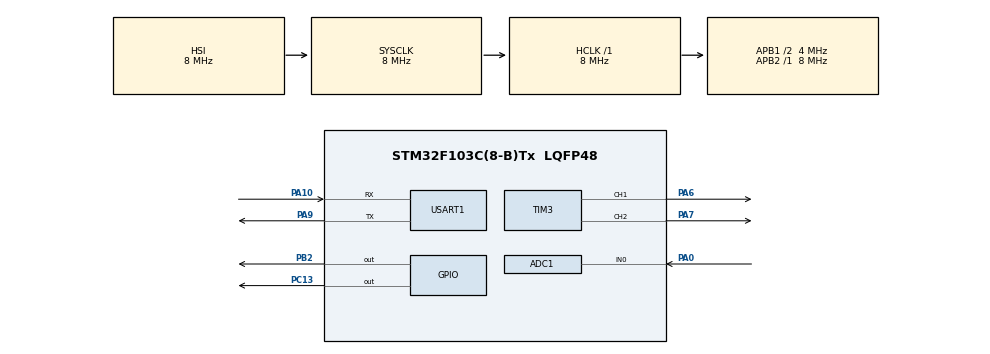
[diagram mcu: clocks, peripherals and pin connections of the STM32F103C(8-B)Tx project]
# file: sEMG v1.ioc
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ADC1.Channel-5\#ChannelRegularConversion=ADC_CHANNEL_0
ADC1.NbrOfConversionFlag=1
ADC1.Rank-5\#ChannelRegularConversion=1
ADC1.SamplingTime-5\#ChannelRegularConversion=ADC_SAMPLETIME_1CYCLE_5
ADC1.master=1
Mcu.Family=STM32F1
Mcu.Name=STM32F103C(8-B)Tx
Mcu.Package=LQFP48
NVIC.PriorityGroup=NVIC_PRIORITYGROUP_4
PA0-WKUP.Signal=ADCx_IN0
PA10.Mode=Asynchronous
PA10.Signal=USART1_RX
PA13.Signal=SYS_JTMS-SWDIO
PA14.Signal=SYS_JTCK-SWCLK
PA6.Signal=S_TIM3_CH1
PA7.Signal=S_TIM3_CH2
PA9.Mode=Asynchronous
PA9.Signal=USART1_TX
PB2.Signal=GPIO_Output
PC13-TAMPER-RTC.Signal=GPIO_Output
PD0-OSC_IN.Mode=HSE-External-Oscillator
PD0-OSC_IN.Signal=RCC_OSC_IN
PD1-OSC_OUT.Mode=HSE-External-Oscillator
PD1-OSC_OUT.Signal=RCC_OSC_OUT
ProjectManager.HeapSize=0x200
ProjectManager.StackSize=0x400
ProjectManager.TargetToolchain=STM32CubeIDE
RCC.ADCPresc=RCC_ADCPCLK2_DIV6
RCC.AHBFreq_Value=8000000
RCC.APB1CLKDivider=RCC_HCLK_DIV2
RCC.APB1Freq_Value=4000000
RCC.APB1TimFreq_Value=8000000
RCC.APB2Freq_Value=8000000
RCC.APB2TimFreq_Value=8000000
RCC.HCLKFreq_Value=8000000
RCC.PLLMUL=RCC_PLL_MUL9
RCC.PLLSourceVirtual=RCC_PLLSOURCE_HSE
RCC.SYSCLKFreq_VALUE=8000000
RCC.USBFreq_Value=72000000
SH.ADCx_IN0.0=ADC1_IN0,IN0
SH.S_TIM3_CH1.0=TIM3_CH1,PWM Generation1 CH1
SH.S_TIM3_CH2.0=TIM3_CH2,PWM Generation2 CH2
TIM3.Channel-PWM\ Generation1\ CH1=TIM_CHANNEL_1
TIM3.Channel-PWM\ Generation2\ CH2=TIM_CHANNEL_2
USART1.VirtualMode=VM_ASYNC
VP_SYS_VS_ND.Mode=No_Debug
board=custom

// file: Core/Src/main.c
/* USER CODE BEGIN Header */
/**
  ******************************************************************************
  * @file           : main.c
  * @brief          : Main program body
  ******************************************************************************
  * @attention
  *
  * Copyright (c) 2026 STMicroelectronics.
  * All rights reserved.
  *
  * This software is licensed under terms that can be found in the LICENSE file
  * in the root directory of this software component.
  * If no LICENSE file comes with this software, it is provided AS-IS.
  *
  ******************************************************************************
  */
/* USER CODE END Header */
#include "main.h"

ADC_HandleTypeDef hadc1;

TIM_HandleTypeDef htim3;

UART_HandleTypeDef huart1;

void SystemClock_Config(void);
static void MX_GPIO_Init(void);
static void MX_ADC1_Init(void);
static void MX_USART1_UART_Init(void);
static void MX_TIM3_Init(void);

int main(void)
{

  /* USER CODE BEGIN 1 */
		  __HAL_RCC_GPIOB_CLK_ENABLE();
		  GPIO_InitTypeDef testLed = {0};
		  testLed.Pin = GPIO_PIN_2;
		  testLed.Mode = GPIO_MODE_OUTPUT_PP;
		  testLed.Pull = GPIO_NOPULL;
		  testLed.Speed = GPIO_SPEED_FREQ_LOW;
		  HAL_GPIO_Init(GPIOB, &testLed);

		  for(int i = 0; i < 10; i++)
		  {
		    HAL_GPIO_TogglePin(GPIOB, GPIO_PIN_2);
		    for(volatile int j = 0; j < 500000; j++); // busy-wait delay, doesn't depend on clock config
		  }
  /* USER CODE END 1 */

  /* MCU Configuration--------------------------------------------------------*/

  /* Reset of all peripherals, Initializes the Flash interface and the Systick. */
  HAL_Init();

  /* Configure the system clock */
  SystemClock_Config();

  /* Initialize all configured peripherals */
  MX_GPIO_Init();
  MX_ADC1_Init();
  MX_USART1_UART_Init();
  MX_TIM3_Init();

  /* Infinite loop */
  while (1)
  {

    /* USER CODE BEGIN 3 */
    HAL_GPIO_TogglePin(GPIOB, GPIO_PIN_2);
    for(volatile int j = 0; j < 1000000; j++);
  }
  /* USER CODE END 3 */
}

void SystemClock_Config(void)
{
  RCC_OscInitTypeDef RCC_OscInitStruct = {0};
  RCC_ClkInitTypeDef RCC_ClkInitStruct = {0};
  RCC_PeriphCLKInitTypeDef PeriphClkInit = {0};

  /** Initializes the RCC Oscillators according to the specified parameters
  * in the RCC_OscInitTypeDef structure.
  */
  RCC_OscInitStruct.OscillatorType = RCC_OSCILLATORTYPE_HSI;
  RCC_OscInitStruct.HSIState = RCC_HSI_ON;
  RCC_OscInitStruct.HSICalibrationValue = RCC_HSICALIBRATION_DEFAULT;
  RCC_OscInitStruct.PLL.PLLState = RCC_PLL_NONE;
  if (HAL_RCC_OscConfig(&RCC_OscInitStruct) != HAL_OK)
  {
    Error_Handler();
  }

  /** Initializes the CPU, AHB and APB buses clocks
  */
  RCC_ClkInitStruct.ClockType = RCC_CLOCKTYPE_HCLK|RCC_CLOCKTYPE_SYSCLK
                              |RCC_CLOCKTYPE_PCLK1|RCC_CLOCKTYPE_PCLK2;
  RCC_ClkInitStruct.SYSCLKSource = RCC_SYSCLKSOURCE_HSI;
  RCC_ClkInitStruct.AHBCLKDivider = RCC_SYSCLK_DIV1;
  RCC_ClkInitStruct.APB1CLKDivider = RCC_HCLK_DIV2;
  RCC_ClkInitStruct.APB2CLKDivider = RCC_HCLK_DIV1;

  if (HAL_RCC_ClockConfig(&RCC_ClkInitStruct, FLASH_LATENCY_0) != HAL_OK)
  {
    Error_Handler();
  }
  PeriphClkInit.PeriphClockSelection = RCC_PERIPHCLK_ADC;
  PeriphClkInit.AdcClockSelection = RCC_ADCPCLK2_DIV6;
  if (HAL_RCCEx_PeriphCLKConfig(&PeriphClkInit) != HAL_OK)
  {
    Error_Handler();
  }
}

static void MX_ADC1_Init(void)
{

  ADC_ChannelConfTypeDef sConfig = {0};

  /** Common config
  */
  hadc1.Instance = ADC1;
  hadc1.Init.ScanConvMode = ADC_SCAN_DISABLE;
  hadc1.Init.ContinuousConvMode = DISABLE;
  hadc1.Init.DiscontinuousConvMode = DISABLE;
  hadc1.Init.ExternalTrigConv = ADC_SOFTWARE_START;
  hadc1.Init.DataAlign = ADC_DATAALIGN_RIGHT;
  hadc1.Init.NbrOfConversion = 1;
  if (HAL_ADC_Init(&hadc1) != HAL_OK)
  {
    Error_Handler();
  }

  /** Configure Regular Channel
  */
  sConfig.Channel = ADC_CHANNEL_0;
  sConfig.Rank = ADC_REGULAR_RANK_1;
  sConfig.SamplingTime = ADC_SAMPLETIME_1CYCLE_5;
  if (HAL_ADC_ConfigChannel(&hadc1, &sConfig) != HAL_OK)
  {
    Error_Handler();
  }

}

static void MX_TIM3_Init(void)
{

  TIM_MasterConfigTypeDef sMasterConfig = {0};
  TIM_OC_InitTypeDef sConfigOC = {0};

  htim3.Instance = TIM3;
  htim3.Init.Prescaler = 0;
  htim3.Init.CounterMode = TIM_COUNTERMODE_UP;
  htim3.Init.Period = 65535;
  htim3.Init.ClockDivision = TIM_CLOCKDIVISION_DIV1;
  htim3.Init.AutoReloadPreload = TIM_AUTORELOAD_PRELOAD_DISABLE;
  if (HAL_TIM_PWM_Init(&htim3) != HAL_OK)
  {
    Error_Handler();
  }
  sMasterConfig.MasterOutputTrigger = TIM_TRGO_RESET;
  sMasterConfig.MasterSlaveMode = TIM_MASTERSLAVEMODE_DISABLE;
  if (HAL_TIMEx_MasterConfigSynchronization(&htim3, &sMasterConfig) != HAL_OK)
  {
    Error_Handler();
  }
  sConfigOC.OCMode = TIM_OCMODE_PWM1;
  sConfigOC.Pulse = 0;
  sConfigOC.OCPolarity = TIM_OCPOLARITY_HIGH;
  sConfigOC.OCFastMode = TIM_OCFAST_DISABLE;
  if (HAL_TIM_PWM_ConfigChannel(&htim3, &sConfigOC, TIM_CHANNEL_1) != HAL_OK)
  {
    Error_Handler();
  }
  if (HAL_TIM_PWM_ConfigChannel(&htim3, &sConfigOC, TIM_CHANNEL_2) != HAL_OK)
  {
    Error_Handler();
  }
  HAL_TIM_MspPostInit(&htim3);

}

static void MX_USART1_UART_Init(void)
{

  huart1.Instance = USART1;
  huart1.Init.BaudRate = 115200;
  huart1.Init.WordLength = UART_WORDLENGTH_8B;
  huart1.Init.StopBits = UART_STOPBITS_1;
  huart1.Init.Parity = UART_PARITY_NONE;
  huart1.Init.Mode = UART_MODE_TX_RX;
  huart1.Init.HwFlowCtl = UART_HWCONTROL_NONE;
  huart1.Init.OverSampling = UART_OVERSAMPLING_16;
  if (HAL_UART_Init(&huart1) != HAL_OK)
  {
    Error_Handler();
  }

}

static void MX_GPIO_Init(void)
{
  GPIO_InitTypeDef GPIO_InitStruct = {0};

  /* GPIO Ports Clock Enable */
  __HAL_RCC_GPIOC_CLK_ENABLE();
  __HAL_RCC_GPIOD_CLK_ENABLE();
  __HAL_RCC_GPIOA_CLK_ENABLE();
  __HAL_RCC_GPIOB_CLK_ENABLE();

  /*Configure GPIO pin Output Level */
  HAL_GPIO_WritePin(GPIOC, GPIO_PIN_13, GPIO_PIN_RESET);

  /*Configure GPIO pin Output Level */
  HAL_GPIO_WritePin(GPIOB, GPIO_PIN_2, GPIO_PIN_RESET);

  /*Configure GPIO pin : PC13 */
  GPIO_InitStruct.Pin = GPIO_PIN_13;
  GPIO_InitStruct.Mode = GPIO_MODE_OUTPUT_PP;
  GPIO_InitStruct.Pull = GPIO_NOPULL;
  GPIO_InitStruct.Speed = GPIO_SPEED_FREQ_LOW;
  HAL_GPIO_Init(GPIOC, &GPIO_InitStruct);

  /*Configure GPIO pin : PB2 */
  GPIO_InitStruct.Pin = GPIO_PIN_2;
  GPIO_InitStruct.Mode = GPIO_MODE_OUTPUT_PP;
  GPIO_InitStruct.Pull = GPIO_NOPULL;
  GPIO_InitStruct.Speed = GPIO_SPEED_FREQ_LOW;
  HAL_GPIO_Init(GPIOB, &GPIO_InitStruct);

}

void Error_Handler(void)
{
  __disable_irq();
  while (1)
  {
  }
}
